VERSION ""

NS_ :

BS_:

BU_: BMS Third_Party_Device

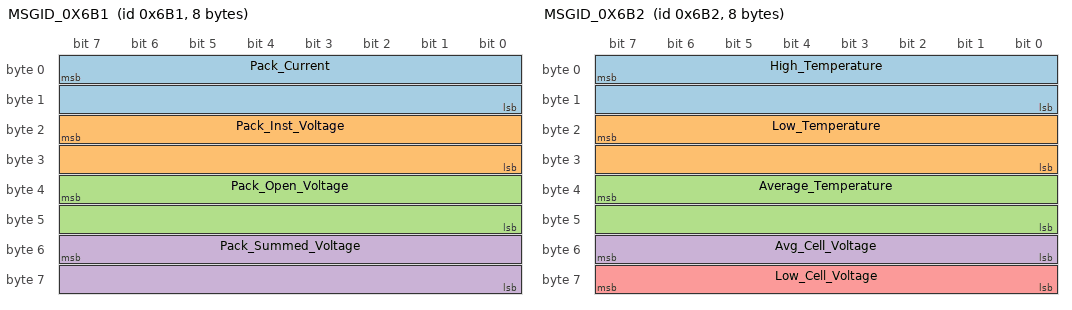
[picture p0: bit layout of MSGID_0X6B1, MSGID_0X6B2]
BO_ 1713 MSGID_0X6B1: 8 BMS
 SG_ Pack_Current : 7|16@0+ (0.1,0) [0|0] "Amps"  Third_Party_Device
 SG_ Pack_Inst_Voltage : 23|16@0+ (0.1,0) [0|0] "Volts"  Third_Party_Device
 SG_ Pack_Open_Voltage : 39|16@0+ (0.1,0) [0|0] "Volts"  Third_Party_Device
 SG_ Pack_Summed_Voltage : 55|16@0+ (0.01,0) [0|0] "Volts"  Third_Party_Device

BO_ 1714 MSGID_0X6B2: 8 BMS
 SG_ High_Temperature : 7|16@0+ (1.0,0) [0|0] "Celsius"  Third_Party_Device
 SG_ Low_Temperature : 23|16@0+ (1.0,0) [0|0] "Celsius"  Third_Party_Device
 SG_ Average_Temperature : 39|16@0+ (1.0,0) [0|0] "Celsius"  Third_Party_Device
 SG_ Avg_Cell_Voltage : 55|8@0+ (1.0E-4,0) [0|0] "Volts"  Third_Party_Device
 SG_ Low_Cell_Voltage : 63|8@0+ (1.0E-4,0) [0|0] "Volts"  Third_Party_Device

BO_ 1715 MSGID_0X6B3: 1 BMS
 SG_ Pack_SOC : 7|8@0+ (0.5,0) [0|0] "Percent"  Third_Party_Device

CM_ BO_ 1713 "This ID Transmits at 8 ms.";
CM_ BO_ 1714 "This ID Transmits at 8 ms.";
CM_ BO_ 1715 "This ID Transmits at 104 ms.";
